AUTOSAR XML (schema 4.0)
package /primatec/light/lceMaster
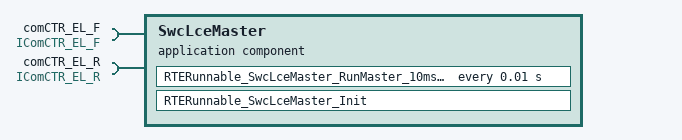
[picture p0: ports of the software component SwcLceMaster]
  application sw component type SwcLceMaster
    require port comCTR_EL_F: required-interface=IComCTR_EL_F
    require port comCTR_EL_R: required-interface=IComCTR_EL_R
    behavior SwcLceMaster_DefaultBehavior
      timing event periodRunnable_LceMaster10ms: start-on-event=RTERunnable_SwcLceMaster_RunMaster_10msTask, period=0.01
      runnable RTERunnable_SwcLceMaster_Init
      runnable RTERunnable_SwcLceMaster_RunMaster_10msTask: can-be-invoked-concurrently=true
        data-receive-point-by-arguments:
          6 x access:
            DRPA_comCTR_EL_F_CTR_FN_DR: accessed-variable=comCTR_EL_F.CTR_FN_DR
            DRPA_comCTR_EL_F_CTR_FN_POS: accessed-variable=comCTR_EL_F.CTR_FN_POS
            DRPA_comCTR_EL_F_CTR_FN_PAR: accessed-variable=comCTR_EL_F.CTR_FN_PAR
            DRPA_comCTR_EL_R_CTR_FN_DR: accessed-variable=comCTR_EL_R.CTR_FN_DR
            DRPA_comCTR_EL_R_CTR_FN_POS: accessed-variable=comCTR_EL_R.CTR_FN_POS
            DRPA_comCTR_EL_R_CTR_FN_PAR: accessed-variable=comCTR_EL_R.CTR_FN_PAR
